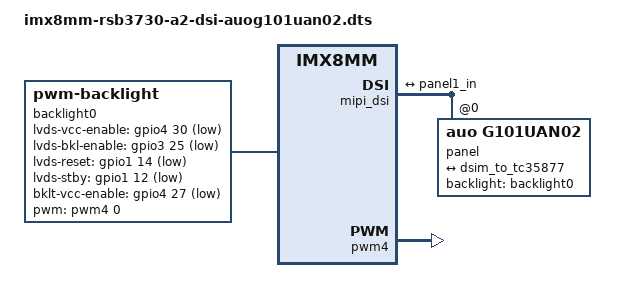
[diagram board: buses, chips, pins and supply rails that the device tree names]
// SPDX-License-Identifier: (GPL-2.0+ OR MIT)
/*
 * Copyright 2019 NXP
 */

/dts-v1/;

#include "imx8mm-rsb3730-a2.dts"

/ {
	backlight0: backlight@0 {
                compatible = "pwm-backlight";
                pwms = <&pwm4 0 1000000 0>;
                brightness-levels = < 0  1  2  3  4  5  6  7  8  9
                             10 11 12 13 14 15 16 17 18 19
                             20 21 22 23 24 25 26 27 28 29
                             30 31 32 33 34 35 36 37 38 39
                             40 41 42 43 44 45 46 47 48 49
                             50 51 52 53 54 55 56 57 58 59
                             60 61 62 63 64 65 66 67 68 69
                             70 71 72 73 74 75 76 77 78 79
                             80 81 82 83 84 85 86 87 88 89
                             90 91 92 93 94 95 96 97 98 99
                            100>;
                default-brightness-level = <80>;
                default-enable = <0>;
        };
};

&lt9611uxc {
	status = "disabled";
	/delete-node/ ports;
};

&mipi_dsi {
	/delete-node/ port@1;

	panel@0 {
		compatible = "auo,g101uan02";
		backlight=<&backlight0>;
		reg = <0>;
		port {
			panel1_in: endpoint {
				remote-endpoint = <&dsim_to_tc35877>;
			};
		};
	};

	port@1 {
		dsim_to_tc35877: endpoint {
			remote-endpoint = <&panel1_in>;
		};
	};
};

&pwm4 {
	status = "okay";
};

&backlight0 {
        pinctrl-names = "default";
        pinctrl-0 = <&pinctrl_bkl>;
        lvds-vcc-enable = <&gpio4 30 1>;
        lvds-bkl-enable = <&gpio3 25 1>;
        lvds-reset=<&gpio1 14 1>;
        lvds-stby=<&gpio1 12 1>;
        bklt-vcc-enable = <&gpio4 27 1>;
        status = "okay";
};

&iomuxc {
	pinctrl_bkl: bklgrp {
                fsl,pins = <
                        MX8MM_IOMUXC_SAI3_RXD_GPIO4_IO30	0x10		/* LCD0_VDD_EN */
                        MX8MM_IOMUXC_SAI2_MCLK_GPIO4_IO27	0x19		/* LCD0_BKLT_PWR_EN */
                        MX8MM_IOMUXC_SAI5_MCLK_GPIO3_IO25	0x19		/* LCD0_BKLT_EN */
                        MX8MM_IOMUXC_GPIO1_IO12_GPIO1_IO12	0x19		/* LVDS_STBY */
                        MX8MM_IOMUXC_GPIO1_IO14_GPIO1_IO14	0x19		/* LVDS_RESET */
                >;
        };
};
